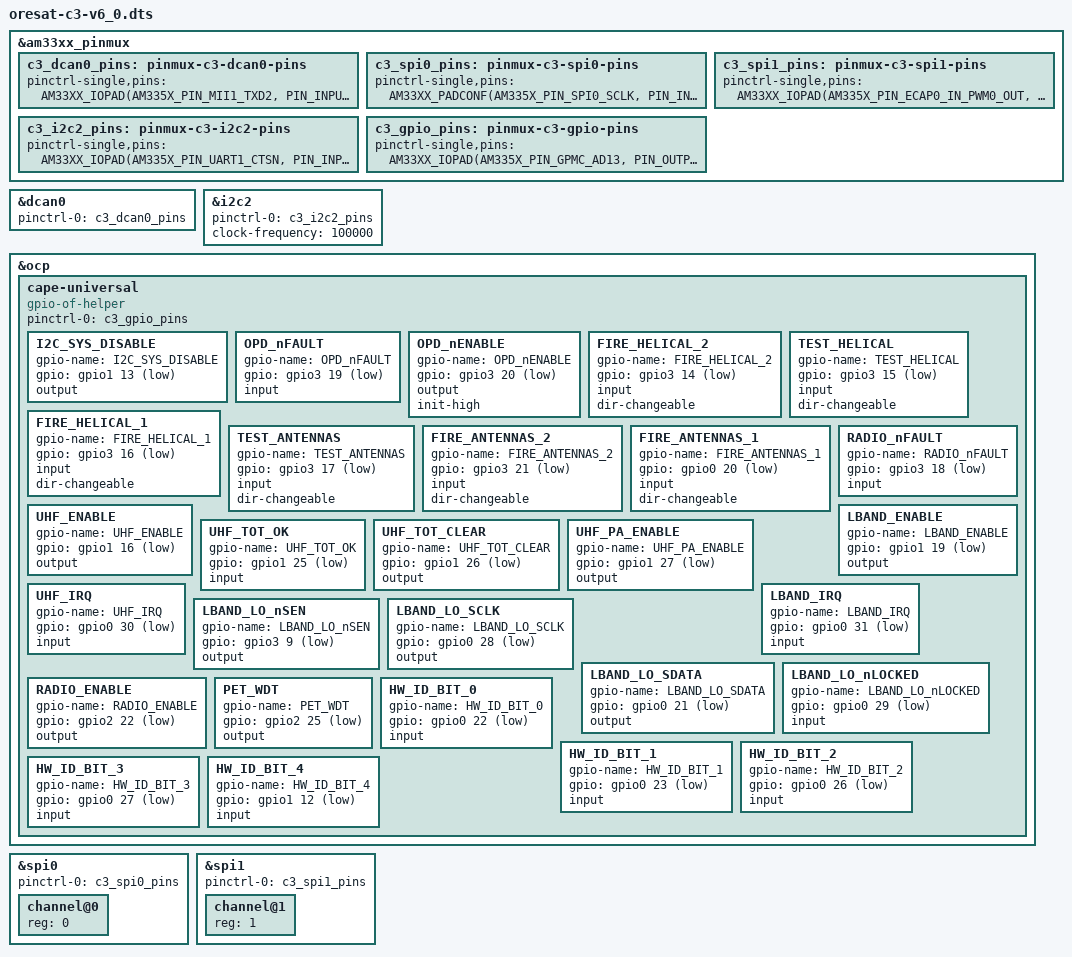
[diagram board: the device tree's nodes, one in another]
/* OreSat C3 v6.0 device tree */

/dts-v1/;

#include "oresat-base.dtsi"

&am33xx_pinmux {
  c3_dcan0_pins: pinmux-c3-dcan0-pins {
    pinctrl-single,pins = <
      AM33XX_IOPAD(AM335X_PIN_MII1_TXD2, PIN_INPUT_PULLUP | MUX_MODE1) /* dcan0_rx */
      AM33XX_IOPAD(AM335X_PIN_MII1_TXD3, PIN_OUTPUT_PULLUP | MUX_MODE1) /* dcan0_tx */
    >;
  };

  c3_spi0_pins: pinmux-c3-spi0-pins {
    pinctrl-single,pins = <
      AM33XX_PADCONF(AM335X_PIN_SPI0_SCLK, PIN_INPUT_PULLUP, MUX_MODE0) /* spi0_sclk */
      AM33XX_PADCONF(AM335X_PIN_SPI0_D0, PIN_INPUT_PULLUP, MUX_MODE0) /* spi0_d0 */
      AM33XX_PADCONF(AM335X_PIN_SPI0_D1, PIN_OUTPUT_PULLUP, MUX_MODE0) /* spi0_d1 */
      AM33XX_PADCONF(AM335X_PIN_SPI0_CS0, PIN_OUTPUT_PULLUP, MUX_MODE0) /* spi0_cs0 */
    >;
  };

  c3_spi1_pins: pinmux-c3-spi1-pins {
    pinctrl-single,pins = <
      AM33XX_IOPAD(AM335X_PIN_ECAP0_IN_PWM0_OUT, PIN_INPUT_PULLUP | MUX_MODE4) /* spi1_sclk */
      AM33XX_IOPAD(AM335X_PIN_UART0_CTSN, PIN_INPUT_PULLUP | MUX_MODE4) /* spi1_d0 */
      AM33XX_IOPAD(AM335X_PIN_UART0_RTSN, PIN_OUTPUT_PULLUP | MUX_MODE4) /* spi1_d1 */
      AM33XX_IOPAD(AM335X_PIN_XDMA_EVENT_INTR0, PIN_OUTPUT_PULLUP | MUX_MODE4) /* spi1_cs1 */
    >;
  };

  c3_i2c2_pins: pinmux-c3-i2c2-pins {
    pinctrl-single,pins = <
      AM33XX_IOPAD(AM335X_PIN_UART1_CTSN, PIN_INPUT | MUX_MODE3) /* i2c2_sda */
      AM33XX_IOPAD(AM335X_PIN_UART1_RTSN, PIN_INPUT | MUX_MODE3) /* i2c2_scl */
    >;
  };

  c3_gpio_pins: pinmux-c3-gpio-pins {
    pinctrl-single,pins = <
      /* i2c sys */
      AM33XX_IOPAD(AM335X_PIN_GPMC_AD13, PIN_OUTPUT | MUX_MODE7) /* gpio1_13 / I2C_SYS_DISABLE */
      /* opd */
      AM33XX_IOPAD(AM335X_PIN_MCASP0_FSR, PIN_INPUT | MUX_MODE7) /* gpio3_19 / OPD_nFAULT */
      AM33XX_IOPAD(AM335X_PIN_MCASP0_AXR1, PIN_OUTPUT | MUX_MODE7) /* gpio3_20 / OPD_nENABLE */
      /* antennas - set these to input by default, let sw swap direction */
      AM33XX_IOPAD(AM335X_PIN_MCASP0_ACLKX, PIN_INPUT | MUX_MODE7) /* gpio3_14 / FIRE_HELICAL_2 */
      AM33XX_IOPAD(AM335X_PIN_MCASP0_FSX, PIN_INPUT | MUX_MODE7) /* gpio3_15 / TEST_HELICAL */
      AM33XX_IOPAD(AM335X_PIN_MCASP0_AXR0, PIN_INPUT | MUX_MODE7) /* gpio3_16 / FIRE_HELICAL_1 */
      AM33XX_IOPAD(AM335X_PIN_MCASP0_AHCLKR, PIN_INPUT | MUX_MODE7) /* gpio3_17 / TEST_ANTENNAS */
      AM33XX_IOPAD(AM335X_PIN_MCASP0_AHCLKX, PIN_INPUT | MUX_MODE7) /* gpio3_21 / FIRE_ANTENNAS_2 */
      AM33XX_IOPAD(AM335X_PIN_XDMA_EVENT_INTR1, PIN_INPUT | MUX_MODE7) /* gpio0_20 / FIRE_ANTENNAS_1 */
      /* radios */
      AM33XX_IOPAD(AM335X_PIN_MCASP0_ACLKR, PIN_INPUT | MUX_MODE7) /* gpio3_18 / RADIO_nFAULT */
      AM33XX_IOPAD(AM335X_PIN_GPMC_A0, PIN_OUTPUT | MUX_MODE7) /* gpio1_16 / UHF_ENABLE */
      AM33XX_IOPAD(AM335X_PIN_GPMC_A3, PIN_OUTPUT | MUX_MODE7) /* gpio1_19 / LBAND_ENABLE */
      AM33XX_IOPAD(AM335X_PIN_GPMC_A9, PIN_INPUT | MUX_MODE7) /* gpio1_25 / UHF_TOT_OK */
      AM33XX_IOPAD(AM335X_PIN_GPMC_A10, PIN_OUTPUT | MUX_MODE7) /* gpio1_26 / UHF_TOT_CLEAR */
      AM33XX_IOPAD(AM335X_PIN_GPMC_A11, PIN_OUTPUT | MUX_MODE7) /* gpio1_27 / UHF_PA_ENABLE */
      AM33XX_IOPAD(AM335X_PIN_GPMC_WAIT0, PIN_INPUT | PIN_INPUT_PULLDOWN | MUX_MODE7) /* gpio0_30 / UHF_IRQ */
      AM33XX_IOPAD(AM335X_PIN_GPMC_WPN, PIN_INPUT | PIN_INPUT_PULLDOWN | MUX_MODE7) /* gpio0_31 / LBAND_IRQ */
      AM33XX_IOPAD(AM335X_PIN_MII1_TX_CLK, PIN_OUTPUT | MUX_MODE7) /* gpio3_9 / LBAND_LO_nSEN */
      AM33XX_IOPAD(AM335X_PIN_MII1_TXD0, PIN_OUTPUT | MUX_MODE7) /* gpio0_28 / LBAND_LO_SCLK */
      AM33XX_IOPAD(AM335X_PIN_MII1_TXD1, PIN_OUTPUT | MUX_MODE7) /* gpio0_21 / LBAND_LO_SDATA */
      AM33XX_IOPAD(AM335X_PIN_RMII1_REF_CLK, PIN_INPUT | MUX_MODE7) /* gpio0_29 / LBAND_LO_nLOCKED */
      AM33XX_IOPAD(AM335X_PIN_LCD_VSYNC, PIN_OUTPUT | MUX_MODE7) /* gpio2_22 / RADIO_ENABLE */
      /* wdt */
      AM33XX_IOPAD(AM335X_PIN_LCD_AC_BIAS_EN, PIN_OUTPUT | MUX_MODE7) /* gpio2_25 / PET_WDT */
      /* hw id */
      AM33XX_IOPAD(AM335X_PIN_GPMC_AD8, PIN_INPUT | MUX_MODE7) /* gpio0_22 / HW_ID_BIT_0 */
      AM33XX_IOPAD(AM335X_PIN_GPMC_AD9, PIN_INPUT | MUX_MODE7) /* gpio0_23 / HW_ID_BIT_1 */
      AM33XX_IOPAD(AM335X_PIN_GPMC_AD10, PIN_INPUT | MUX_MODE7) /* gpio0_26 / HW_ID_BIT_2 */
      AM33XX_IOPAD(AM335X_PIN_GPMC_AD11, PIN_INPUT | MUX_MODE7) /* gpio0_27 / HW_ID_BIT_3 */
      AM33XX_IOPAD(AM335X_PIN_GPMC_AD12, PIN_INPUT | MUX_MODE7) /* gpio1_12 / HW_ID_BIT_4 */
    >;
  };
};

&dcan0 {
  status = "okay";
  pinctrl-names = "default";
  pinctrl-0 = <&c3_dcan0_pins>;
};

&i2c2 {
  #address-cells = <1>;
  #size-cells = <0>;
  status = "okay";
  pinctrl-names = "default";
  pinctrl-0 = <&c3_i2c2_pins>;
  clock-frequency = <100000>;
};

&ocp {
  cape-universal {
    compatible = "gpio-of-helper";
    status = "okay";
    pinctrl-names = "default";
    pinctrl-0 = <&c3_gpio_pins>;

    I2C_SYS_DISABLE {
      gpio-name = "I2C_SYS_DISABLE";
      gpio = <&gpio1 13 GPIO_ACTIVE_LOW>; /* AM335X_PIN_GPMC_A13 */
      output;
    };

    OPD_nFAULT {
      gpio-name = "OPD_nFAULT";
      gpio = <&gpio3 19 GPIO_ACTIVE_LOW>; /* AM335X_PIN_MCASP0_FSR */
      input;
    };

    OPD_nENABLE {
      gpio-name = "OPD_nENABLE";
      gpio = <&gpio3 20 GPIO_ACTIVE_LOW>; /* AM335X_PIN_MCASP0_AXR1 */
      output;
      init-high;
    };

    FIRE_HELICAL_2 {
      gpio-name = "FIRE_HELICAL_2";
      gpio = <&gpio3 14 GPIO_ACTIVE_LOW>; /* AM335X_PIN_MCASP0_ACLKX */
      input;
      dir-changeable;
    };

    TEST_HELICAL {
      gpio-name = "TEST_HELICAL";
      gpio = <&gpio3 15 GPIO_ACTIVE_LOW>; /* AM335X_PIN_MCASP0_FSX */
      input;
      dir-changeable;
    };

    FIRE_HELICAL_1 {
      gpio-name = "FIRE_HELICAL_1";
      gpio = <&gpio3 16 GPIO_ACTIVE_LOW>; /* AM335X_PIN_MCASP0_AXR0 */
      input;
      dir-changeable;
    };

    TEST_ANTENNAS {
      gpio-name = "TEST_ANTENNAS";
      gpio = <&gpio3 17 GPIO_ACTIVE_LOW>; /* AM335X_PIN_MCASP0_AHCLKR */
      input;
      dir-changeable;
    };

    FIRE_ANTENNAS_2 {
      gpio-name = "FIRE_ANTENNAS_2";
      gpio = <&gpio3 21 GPIO_ACTIVE_LOW>; /* AM335X_PIN_MCASP0_AHCLKX */
      input;
      dir-changeable;
    };

    FIRE_ANTENNAS_1 {
      gpio-name = "FIRE_ANTENNAS_1";
      gpio = <&gpio0 20 GPIO_ACTIVE_LOW>; /* AM335X_PIN_XDMA_EVENT_INTR1 */
      input;
      dir-changeable;
    };

    RADIO_nFAULT {
      gpio-name = "RADIO_nFAULT";
      gpio = <&gpio3 18 GPIO_ACTIVE_LOW>; /* AM335X_PIN_MCASP0_ACLKR */
      input;
    };

    UHF_ENABLE {
      gpio-name = "UHF_ENABLE";
      gpio = <&gpio1 16 GPIO_ACTIVE_LOW>; /* AM335X_PIN_GPMC_A0 */
      output;
    };

    LBAND_ENABLE {
      gpio-name = "LBAND_ENABLE";
      gpio = <&gpio1 19 GPIO_ACTIVE_LOW>; /* AM335X_PIN_GPMC_A3 */
      output;
    };

    UHF_TOT_OK {
      gpio-name = "UHF_TOT_OK";
      gpio = <&gpio1 25 GPIO_ACTIVE_LOW>; /* AM335X_PIN_GPMC_A9 */
      input;
    };

    UHF_TOT_CLEAR {
      gpio-name = "UHF_TOT_CLEAR";
      gpio = <&gpio1 26 GPIO_ACTIVE_LOW>; /* AM335X_PIN_GPMC_A10 */
      output;
    };

    UHF_PA_ENABLE {
      gpio-name = "UHF_PA_ENABLE";
      gpio = <&gpio1 27 GPIO_ACTIVE_LOW>; /* AM335X_PIN_GPMC_A11 */
      output;
    };

    UHF_IRQ {
      gpio-name = "UHF_IRQ";
      gpio = <&gpio0 30 GPIO_ACTIVE_LOW>; /* AM335X_PIN_GPMC_WAIT0 */
      input;
    };

    LBAND_IRQ {
      gpio-name = "LBAND_IRQ";
      gpio = <&gpio0 31 GPIO_ACTIVE_LOW>; /* AM335X_PIN_GPMC_WPN */
      input;
    };

    LBAND_LO_nSEN {
      gpio-name = "LBAND_LO_nSEN";
      gpio = <&gpio3 9 GPIO_ACTIVE_LOW>; /* AM335X_PIN_MII1_TX_CLK */
      output;
    };

    LBAND_LO_SCLK {
      gpio-name = "LBAND_LO_SCLK";
      gpio = <&gpio0 28 GPIO_ACTIVE_LOW>; /* AM335X_PIN_MII1_TXD0 */
      output;
    };

    LBAND_LO_SDATA {
      gpio-name = "LBAND_LO_SDATA";
      gpio = <&gpio0 21 GPIO_ACTIVE_LOW>; /* AM335X_PIN_MII1_TXD1 */
      output;
    };

    LBAND_LO_nLOCKED {
      gpio-name = "LBAND_LO_nLOCKED";
      gpio = <&gpio0 29 GPIO_ACTIVE_LOW>; /* AM335X_PIN_RMII1_REF_CLK */
      input;
    };

    RADIO_ENABLE {
      gpio-name = "RADIO_ENABLE";
      gpio = <&gpio2 22 GPIO_ACTIVE_LOW>; /* AM335X_PIN_LCD_VSYNC */
      output;
    };

    PET_WDT {
      gpio-name = "PET_WDT";
      gpio = <&gpio2 25 GPIO_ACTIVE_LOW>; /* AM335X_PIN_LCD_AC_BIAS_EN */
      output;
    };

    HW_ID_BIT_0 {
      gpio-name = "HW_ID_BIT_0";
      gpio = <&gpio0 22 GPIO_ACTIVE_LOW>; /* AM335X_PIN_GPMC_AD8 */
      input;
    };

    HW_ID_BIT_1 {
      gpio-name = "HW_ID_BIT_1";
      gpio = <&gpio0 23 GPIO_ACTIVE_LOW>; /* AM335X_PIN_GPMC_AD9 */
      input;
    };

    HW_ID_BIT_2 {
      gpio-name = "HW_ID_BIT_2";
      gpio = <&gpio0 26 GPIO_ACTIVE_LOW>; /* AM335X_PIN_GPMC_AD10 */
      input;
    };

    HW_ID_BIT_3 {
      gpio-name = "HW_ID_BIT_3";
      gpio = <&gpio0 27 GPIO_ACTIVE_LOW>; /* AM335X_PIN_GPMC_AD11 */
      input;
    };

    HW_ID_BIT_4 {
      gpio-name = "HW_ID_BIT_4";
      gpio = <&gpio1 12 GPIO_ACTIVE_LOW>; /* AM335X_PIN_GPMC_AD12 */
      input;
    };
  };
};

&spi0 {
  #address-cells = <1>;
  #size-cells = <0>;
  status = "okay";
  pinctrl-names = "default";
  pinctrl-0 = <&c3_spi0_pins>;

  channel@0 {
    status = "okay";
    reg = <0>;
  };
};

&spi1 {
  #address-cells = <1>;
  #size-cells = <0>;
  status = "okay";
  pinctrl-names = "default";
  pinctrl-0 = <&c3_spi1_pins>;

  channel@1 {
    status = "okay";
    reg = <1>;
  };
};

